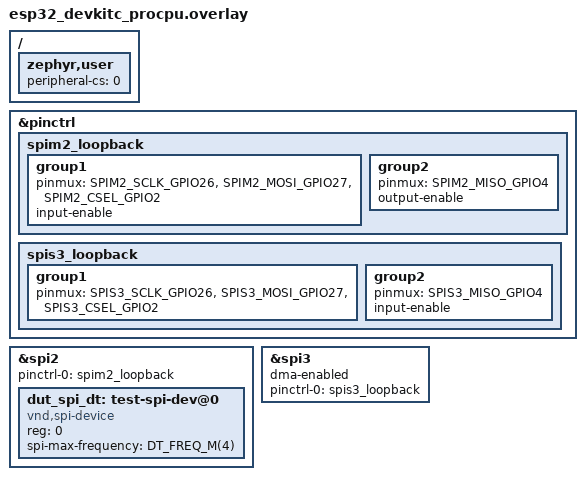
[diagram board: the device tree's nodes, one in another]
/*
 * Copyright (c) 2026 Espressif Systems (Shanghai) Co., Ltd.
 *
 * SPDX-License-Identifier: Apache-2.0
 *
 * SPI controller/target loopback on a single ESP32 using the GPIO matrix.
 * The controller (spi2/HSPI, SPIM2_*) and target (spi3/VSPI, SPIS3_*) share
 * the same pads, so no external wiring is required.
 *
 *   line  shared GPIO  spi2 controller   spi3 target
 *   SCLK  GPIO26       SPIM2_SCLK (out)  SPIS3_SCLK (in)
 *   MOSI  GPIO27       SPIM2_MOSI (out)  SPIS3_MOSI (in)
 *   MISO  GPIO4        SPIM2_MISO (in)   SPIS3_MISO (out)
 *   CS    GPIO2        SPIM2_CSEL (out)  SPIS3_CSEL (in)
 */

#include <dt-bindings/pinctrl/esp32-pinctrl.h>

/ {
	zephyr,user {
		peripheral-cs = <0>;
	};
};

&pinctrl {
	spim2_loopback: spim2_loopback {
		group1 {
			pinmux = <SPIM2_SCLK_GPIO26>,
				 <SPIM2_MOSI_GPIO27>,
				 <SPIM2_CSEL_GPIO2>;
			input-enable; /* preserve controller pad sense for loopback test */
		};

		group2 {
			pinmux = <SPIM2_MISO_GPIO4>;
			output-enable; /* preserve controller pad drive for loopback test */
		};
	};

	spis3_loopback: spis3_loopback {
		group1 {
			pinmux = <SPIS3_SCLK_GPIO26>,
				 <SPIS3_MOSI_GPIO27>,
				 <SPIS3_CSEL_GPIO2>;
		};

		group2 {
			pinmux = <SPIS3_MISO_GPIO4>;
			input-enable; /* preserve controller pad sense for loopback test */
		};
	};
};

&spi2 {
	status = "okay";
	pinctrl-0 = <&spim2_loopback>;
	pinctrl-names = "default";

	dut_spi_dt: test-spi-dev@0 {
		compatible = "vnd,spi-device";
		reg = <0>;
		spi-max-frequency = <DT_FREQ_M(4)>;
	};
};

dut_spis: &spi3 {
	status = "okay";
	dma-enabled;
	pinctrl-0 = <&spis3_loopback>;
	pinctrl-names = "default";
};
